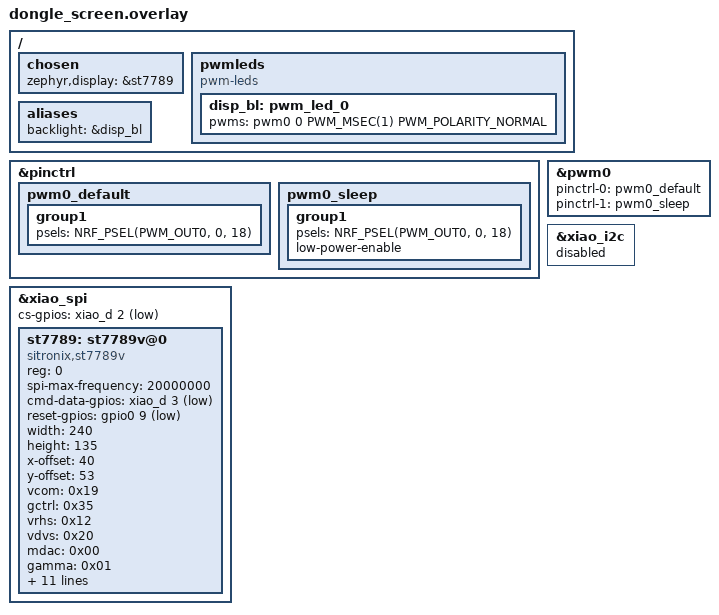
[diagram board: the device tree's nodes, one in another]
/ {
   chosen {
      zephyr,display = &st7789;
   };

   pwmleds: pwmleds {
      compatible = "pwm-leds";
      disp_bl: pwm_led_0 {
         pwms = <&pwm0 0 PWM_MSEC(1) PWM_POLARITY_NORMAL>;
      };
   };

   aliases {
      backlight = &disp_bl;
   };
};

/* バックライト制御ピン: D18 (P0.18) */
&pinctrl {
    pwm0_default: pwm0_default {
        group1 {
            psels = <NRF_PSEL(PWM_OUT0, 0, 18)>;
        };
    };
    pwm0_sleep: pwm0_sleep {
        group1 {
            psels = <NRF_PSEL(PWM_OUT0, 0, 18)>;
            low-power-enable;
        };
    };
};

&pwm0 {
    status = "okay";
    pinctrl-0 = <&pwm0_default>;
    pinctrl-1 = <&pwm0_sleep>;
    pinctrl-names = "default", "sleep";
};

/* ディスプレイ SPI 通信設定 */
&xiao_spi {
    status = "okay";
    cs-gpios = <&xiao_d 2 GPIO_ACTIVE_LOW>; /* D2 */

    st7789: st7789v@0 {
        compatible = "sitronix,st7789v";
        reg = <0>;
        spi-max-frequency = <20000000>;
        cmd-data-gpios = <&xiao_d 3 GPIO_ACTIVE_LOW>; /* D3 */
        reset-gpios = <&gpio0 9 GPIO_ACTIVE_LOW>;    /* D17 (P0.09) */

        /* 横向き 240x135 設定 */
        width = <240>;
        height = <135>;
        x-offset = <40>;
        y-offset = <53>;

        /* ST7789V パネル初期化パラメータ（元のYADSの値をそのまま維持） */
        vcom = <0x19>;
        gctrl = <0x35>;
        vrhs = <0x12>;
        vdvs = <0x20>;
        mdac = <0x00>;
        gamma = <0x01>;
        colmod = <0x05>;
        lcm = <0x2c>;
        porch-param = [0c 0c 00 33 33];
        cmd2en-param = [5a 69 02 01];
        pwctrl1-param = [a4 a1];
        pvgam-param = [d0 04 0d 11 13 2b 3f 54 4c 18 0d 0b 1f 23];
        nvgam-param = [d0 04 0c 11 13 2c 3f 44 51 2f 1f 1f 20 23];
        ram-param = [00 f0];
        rgb-param = [cd 08 14];
    };
};

/* 環境光センサーを使わないため I2C を無効化 */
&xiao_i2c {
    status = "disabled";
};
